# STM32L052 register map
File version: 1.0
CPU: CM0+ r0p0, little endian, MPU, no FPU, 4 interrupt priority bits
Registers are 32-bit, read-write, reset 0x0 unless marked. A register's access mark holds for its fields unless they carry their own. Offsets are from the block's base; lines under a group give offsets from that group; [hi:lo] are bit positions; {n}, {i} and the like mark numbered series; 'fields as' and 'values as' point back to an identical list; <NAME> marks a mode.

## Memory map
0x40000000 TIM2 size 0x400 — General-purpose-timers
0x40000400 TIM3 size 0x400
0x40001000 TIM6 size 0x400 — Basic-timers
0x40001400 TIM7 size 0x400
0x40002800 RTC size 0x400 — Real-time clock
0x40002C00 WWDG size 0x400 — System window watchdog
0x40003000 IWDG size 0x400 — Independent watchdog
0x40003800 SPI2 size 0x400
0x40004400 USART2 size 0x400
0x40004800 LPUSART1 size 0x400 — Universal synchronous asynchronous receiver transmitter
0x40004C00 USART4 size 0x400
0x40005000 USART5 size 0x400
0x40005400 I2C1 size 0x400 — Inter-integrated circuit
0x40005800 I2C2 size 0x400
0x40005C00 USB_FS size 0x400 — Universal serial bus full-speed device interface
0x40006000 USB_SRAM size 0x800 — Universal serial bus full-speed device interface
0x40006C00 CRS size 0x400 — Clock recovery system
0x40007000 PWR size 0x400 — Power control
0x40007400 DAC size 0x400 — Digital-to-analog converter
0x40007800 I2C3 size 0x400
0x40007C00 LPTIM size 0x400 — Low power timer
0x40010000 SYSCFG_COMP size 0x400 — System configuration controller and Comparator
0x40010400 EXTI size 0x400 — External interrupt/event controller
0x40010800 TIM21 size 0x400 — General-purpose-timers
0x40011400 TIM22 size 0x400 — General-purpose-timers
0x40011C00 Firewall size 0x400
0x40012400 ADC size 0x400 — Analog-to-digital converter
0x40013000 SPI1 size 0x400 — Serial peripheral interface
0x40013800 USART1 size 0x400 — Universal synchronous asynchronous receiver transmitter
0x40015800 DBGMCU size 0x400 — Debug support
0x40020000 DMA1 size 0x400 — Direct memory access controller
0x40021000 RCC size 0x400 — Reset and clock control
0x40022000 Flash size 0x400
0x40023000 CRC size 0x400 — Cyclic redundancy check calculation unit
0x40024000 TSC size 0x400 — Touch sensing controller
0x40025000 RNG size 0x400 — Random number generator
0x50000000 GPIOA size 0x400 — General-purpose I/Os
0x50000400 GPIOB size 0x400 — General-purpose I/Os
0x50000800 GPIOC size 0x400
0x50000C00 GPIOD size 0x400
0x50001000 GPIOE size 0x400
0x50001C00 GPIOH size 0x400
0xE000E010 STK size 0x11 — SysTick timer
0xE000E100 NVIC size 0x33D — Nested Vectored Interrupt Controller
0xE000ED00 SCB size 0x41 — System control block
0xE000ED90 MPU size 0x15 — Memory protection unit

## Interrupts
0 WWDG — Window Watchdog interrupt
1 PVD (EXTI) — PVD through EXTI line detection
2 RTC — RTC global interrupt
4 RCC — RCC global interrupt
5 EXTI0_1 (EXTI) — EXTI Line[1:0] interrupts
6 EXTI2_3 (EXTI) — EXTI Line[3:2] interrupts
7 EXTI4_15 (EXTI) — EXTI Line15 and EXTI4 interrupts
8 TSC — Touch sensing interrupt
9 DMA1_Channel1 (DMA1) — DMA1 Channel1 global interrupt
10 DMA1_Channel2_3 (DMA1) — DMA1 Channel2 and 3 interrupts
11 DMA1_Channel4_7 (DMA1) — DMA1 Channel4 to 7 interrupts
12 ADC_COMP (ADC) — ADC and comparator 1 and 2
13 LPTIM1 (LPTIM) — LPTIMER1 interrupt through EXTI29
14 USART4_USART5 (USART4) — USART4/USART5 global interrupt
15 TIM2 — TIM2 global interrupt
16 TIM3 — TIM3 global interrupt
17 TIM6_DAC (TIM6) — TIM6 global interrupt and DAC
18 TIM7 — TIM7 global interrupt and DAC
20 TIM21 — TIMER21 global interrupt
21 I2C3 (PWR) — I2C3 global interrupt
22 TIM22 — TIMER22 global interrupt
23 I2C1 — I2C1 global interrupt
24 I2C2 — I2C2 global interrupt
25 SPI1 — SPI1_global_interrupt
26 SPI2 — SPI2 global interrupt
27 USART1 — USART1 global interrupt
28 USART2 — USART2 global interrupt
31 USB (USB_FS) — USB event interrupt through EXTI18

## DAC — Digital-to-analog converter
Base 0x40007400
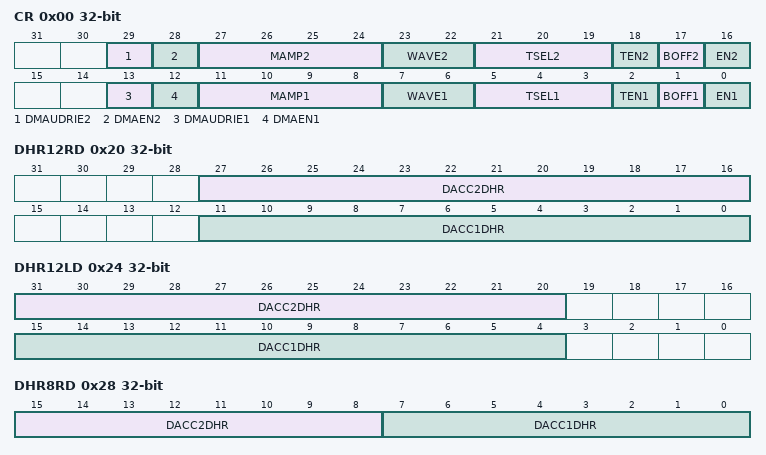
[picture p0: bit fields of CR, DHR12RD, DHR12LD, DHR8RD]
0x00 CR — control register
  [29] DMAUDRIE2 — DAC channel2 DMA underrun interrupt enable
  [28] DMAEN2 — DAC channel2 DMA enable
  [27:24] MAMP2 — DAC channel2 mask/amplitude selector
  [23:22] WAVE2 — DAC channel2 noise/triangle wave generation enable
  [21:19] TSEL2 — DAC channel2 trigger selection
  [18] TEN2 — DAC channel2 trigger enable
  [17] BOFF2 — DAC channel2 output buffer disable
  [16] EN2 — DAC channel2 enable
  [13] DMAUDRIE1 — DAC channel1 DMA Underrun Interrupt enable
  [12] DMAEN1 — DAC channel1 DMA enable
  [11:8] MAMP1 — DAC channel1 mask/amplitude selector
  [7:6] WAVE1 — DAC channel1 noise/triangle wave generation enable
  [5:3] TSEL1 — DAC channel1 trigger selection
  [2] TEN1 — DAC channel1 trigger enable
  [1] BOFF1 — DAC channel1 output buffer disable
  [0] EN1 — DAC channel1 enable
0x04 SWTRIGR wo — software trigger register
  [0] SWTRIG1 — DAC channel1 software trigger
0x08 DHR12R1 — channel1 12-bit right-aligned data holding register
  [11:0] DACC1DHR — DAC channel1 12-bit right-aligned data
0x0C DHR12L1 — channel1 12-bit left-aligned data holding register
  [15:4] DACC1DHR — DAC channel1 12-bit left-aligned data
0x10 DHR8R1 — channel1 8-bit right-aligned data holding register
  [7:0] DACC1DHR — DAC channel1 8-bit right-aligned data
0x14 DHR12R2 — channel2 12-bit right-aligned data holding register
  [11:0] DACC2DHR — DAC channel2 12-bit right-aligned data
0x18 DHR12L2 — channel2 12-bit left-aligned data holding register
  [15:4] DACC2DHR — DAC channel2 12-bit left-aligned data
0x1C DHR8R2 — channel2 8-bit right-aligned data holding register
  [7:0] DACC2DHR — DAC channel2 8-bit right-aligned data
0x20 DHR12RD — Dual DAC 12-bit right-aligned data holding register
  [27:16] DACC2DHR — DAC channel2 12-bit right-aligned data
  [11:0] DACC1DHR — DAC channel1 12-bit right-aligned data
0x24 DHR12LD — Dual DAC 12-bit left-aligned data holding register
  [31:20] DACC2DHR — DAC channel2 12-bit left-aligned data
  [15:4] DACC1DHR — DAC channel1 12-bit left-aligned data
0x28 DHR8RD — Dual DAC 8-bit right-aligned data holding register
  [15:8] DACC2DHR — DAC channel2 8-bit right-aligned data
  [7:0] DACC1DHR — DAC channel1 8-bit right-aligned data
0x2C DOR1 ro — channel1 data output register
  [11:0] DACC1DOR — DAC channel1 data output
0x30 DOR2 ro — channel2 data output register
  [11:0] DACC2DOR — DAC channel2 data output
0x34 SR — status register
  [13] DMAUDR1 — DAC channel1 DMA underrun flag
